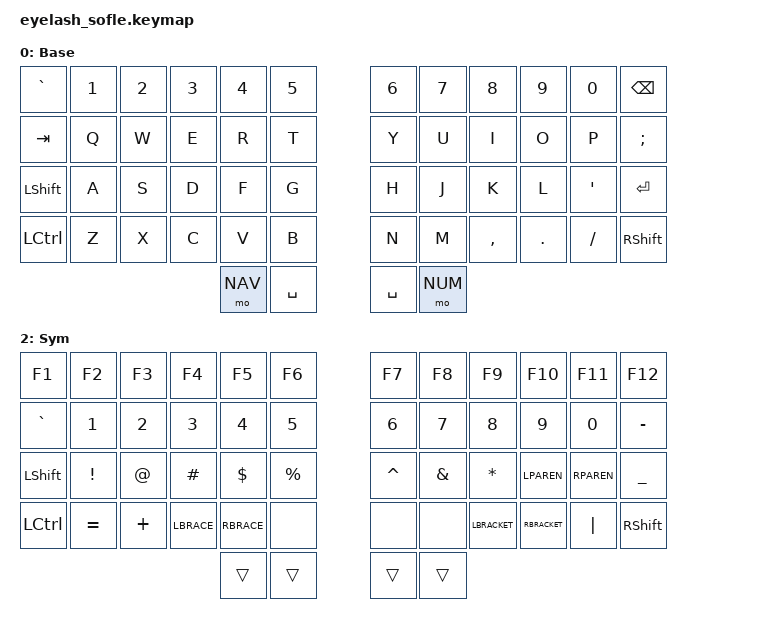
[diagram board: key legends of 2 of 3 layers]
#define ZMK_POINTING_DEFAULT_MOVE_VAL 1200  // 600
#define ZMK_POINTING_DEFAULT_SCRL_VAL 25   // 10

#include <input/processors.dtsi>
#include <zephyr/dt-bindings/input/input-event-codes.h>
#include <behaviors.dtsi>
#include <dt-bindings/zmk/bt.h>
#include <dt-bindings/zmk/keys.h>
#include <dt-bindings/zmk/outputs.h>
#include <dt-bindings/zmk/pointing.h>
#include <dt-bindings/zmk/rgb.h>

&mmv_input_listener { input-processors = <&zip_xy_scaler 2 1>; };

&msc_input_listener { input-processors = <&zip_scroll_scaler 2 1>; };

&msc {
    acceleration-exponent = <1>;      // 0
    time-to-max-speed-ms = <100>;       // 300
    delay-ms = <0>;                   // 0
};

&mmv {
    time-to-max-speed-ms = <500>;
    acceleration-exponent = <1>;
    trigger-period-ms = <16>;
};

&soft_off { hold-time-ms = <2000>; };

/ {
    scroll_encoder: scroll_encoder {
        compatible = "zmk,behavior-sensor-rotate";
        #sensor-binding-cells = <0>;
        bindings = <&msc SCRL_DOWN>, <&msc SCRL_UP>;

        tap-ms = <100>;
    };

    behaviors {
    };

    combos {
        compatible = "zmk,combos";

        softoff {
            bindings = <&soft_off>;
            key-positions = <14 28 40>;
        };
    };

    keymap {
        compatible = "zmk,keymap";

        // ───────────── 0. Base (white) ─────────────
        base_layer {
            bindings = <
                &kp GRAVE &kp N1 &kp N2 &kp N3 &kp N4 &kp N5              &kp N6 &kp N7 &kp N8 &kp N9 &kp N0 &kp BSPC
                &kp TAB   &kp Q  &kp W  &kp E  &kp R  &kp T               &kp Y  &kp U  &kp I  &kp O  &kp P  &kp SCLN
                &kp LSHIFT &kp A &kp S  &kp D  &kp F  &kp G               &kp H  &kp J  &kp K  &kp L  &kp QUOT &kp ENTER
                &kp LCTRL &kp Z &kp X  &kp C  &kp V  &kp B                &kp N  &kp M  &kp COMMA &kp DOT &kp SLASH &kp RSHIFT
                                          &mo NAV &kp SPACE              &kp SPACE &mo NUM
            >;
            sensor-bindings = <&inc_dec_kp C_VOLUME_UP C_VOL_DN>;
            display-name = "Base";
        };

        // ───────────── 1. Nav/Edit (red) ─────────────
        nav_layer {
            label = "NAV";
            bindings = <
                &none     &none      &none      &none      &none      &none
                &kp TAB   &kp INS    &kp LC(C)  &kp LC(X)  &kp LC(V)  &kp CAPSLOCK
                &kp LSHIFT &kp LC(Z) &none      &none      &none      &none
                &kp LCTRL  &none      &none      &none      &none      &none
                                             &trans      &trans      &trans      &trans
            >;
            display-name = "Nav";
            sensor-bindings = <&scroll_encoder>;
        };

        // ───────────── 2. Num/Symbol (blue) ─────────────
        sym_layer {
            label = "NUM";
            bindings = <
                &kp F1 &kp F2 &kp F3 &kp F4 &kp F5 &kp F6                   &kp F7 &kp F8 &kp F9 &kp F10 &kp F11 &kp F12
                &kp GRAVE &kp N1 &kp N2 &kp N3 &kp N4 &kp N5                &kp N6 &kp N7 &kp N8 &kp N9 &kp N0 &kp MINUS
                &kp LSHIFT &kp EXCL &kp AT &kp HASH &kp DOLLAR &kp PERCENT &kp CARET &kp AMPERSAND &kp STAR &kp LPAREN &kp RPAREN &kp UNDERSCORE
                &kp LCTRL &kp EQUAL &kp PLUS &kp LBRACE &kp RBRACE &none   &none &none &kp LBRACKET &kp RBRACKET &kp PIPE &kp RSHIFT
                                           &trans &trans                   &trans &trans
            >;
            display-name = "Sym";
            sensor-bindings = <&scroll_encoder>;
        };
    };
};
